VERSION ""

NS_ :

BS_:

BU_: Tank_Sensor1
VAL_TABLE_ FMS_PushButtonStates 1 "On" 0 "Off" ;
VAL_TABLE_ FMS_SSM 3 "Failure Warning " 2 "Functional Test" 1 "NCD" 0 "Normal Operation " ;
VAL_TABLE_ FMS_SDI 2 "Computer 2" 1 "Computer 1" ;
VAL_TABLE_ FMS_Pump_States 1 "Off" 0 "Energized" ;
VAL_TABLE_ vt_BNRaccuracy 1 "Degraded Accuracy" 0 "Nominal Accuracy" ;
VAL_TABLE_ vt_BCDstatus_above_below 3 "Below" 2 "FT (functional test)" 1 "NCD (no computed data)" 0 "Above" ;
VAL_TABLE_ vt_BCDstatus_to_from 3 "From" 2 "FT (functional test)" 1 "NCD (no computed data)" 0 "To" ;
VAL_TABLE_ vt_BCDstatus_right_left 3 "Left" 2 "FT (functional test)" 1 "NCD (no computed data)" 0 "Right" ;
VAL_TABLE_ vt_BCDstatus_east_west 3 "West" 2 "FT (functional test)" 1 "NCD (no computed data)" 0 "East" ;
VAL_TABLE_ vt_BCDstatus_north_south 3 "South" 2 "FT (functional test)" 1 "NCD (no computed data)" 0 "North" ;
VAL_TABLE_ vt_BCDstatus_plus_minus 3 "Minus" 2 "FT (functional test)" 1 "NCD (no computed data)" 0 "Plus" ;
VAL_TABLE_ vt_DSCstatus 3 "FW (failure warning)" 2 "FT (functional test)" 1 "NCD (no computed data)" 0 "NO (normal operation)" ;
VAL_TABLE_ vt_BNRsign_above_below 1 "Below" 0 "Above" ;
VAL_TABLE_ vt_BNRsign_to_from 1 "From" 0 "To" ;
VAL_TABLE_ vt_BNRsign_right_left 1 "Left" 0 "Right" ;
VAL_TABLE_ vt_BNRsign_east_west 1 "West" 0 "East" ;
VAL_TABLE_ vt_BNRsign_north_south 1 "South" 0 "North" ;
VAL_TABLE_ vt_BNRsign_plus_minus 1 "Minus" 0 "Plus" ;
VAL_TABLE_ vt_BNRstatus 3 "NO (normal operation)" 2 "FT (functional test)" 1 "NCD (no computed data)" 0 "FW (failure warning)" ;

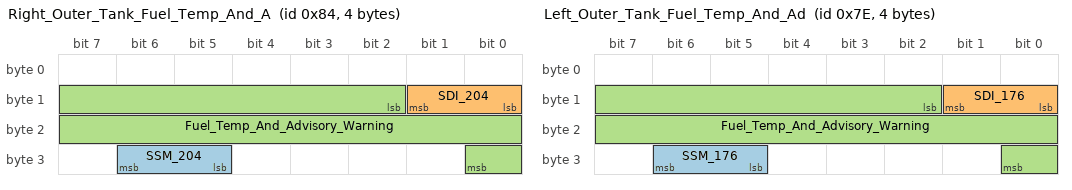
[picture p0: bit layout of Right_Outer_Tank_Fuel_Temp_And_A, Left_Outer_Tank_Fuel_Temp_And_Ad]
BO_ 132 Right_Outer_Tank_Fuel_Temp_And_A: 4 Tank_Sensor1
 SG_ SSM_204 : 29|2@1+ (1,0) [0|3] "" Vector__XXX
 SG_ SDI_204 : 8|2@1+ (1,0) [0|3] "" Vector__XXX
 SG_ Fuel_Temp_And_Advisory_Warning : 10|15@1- (0.25,0) [-512|512] "" Vector__XXX

BO_ 126 Left_Outer_Tank_Fuel_Temp_And_Ad: 4 Tank_Sensor1
 SG_ SSM_176 : 29|2@1+ (1,0) [0|3] "" Vector__XXX
 SG_ SDI_176 : 8|2@1+ (1,0) [0|3] "" Vector__XXX
 SG_ Fuel_Temp_And_Advisory_Warning : 10|15@1- (0.25,0) [-512|512] "" Vector__XXX

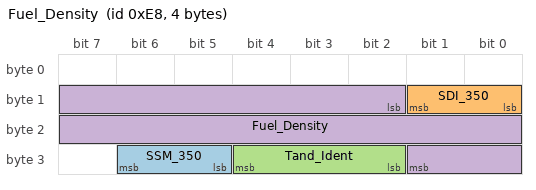
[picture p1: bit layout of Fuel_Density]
BO_ 232 Fuel_Density: 4 Tank_Sensor1
 SG_ SSM_350 : 29|2@1+ (1,0) [0|3] "" Vector__XXX
 SG_ SDI_350 : 8|2@1+ (1,0) [0|3] "" Vector__XXX
 SG_ Tand_Ident : 26|3@1+ (1,0) [0|7] "" Vector__XXX
 SG_ Fuel_Density : 10|16@1- (0.0001,0) [0|1] "kg/l" Vector__XXX

CM_ SG_ 132 SDI_204 "Source/Destination Identifier";
CM_ SG_ 126 SDI_176 "Source/Destination Identifier";
CM_ SG_ 232 SDI_350 "Source/Destination Identifier";
BA_DEF_  "ProtocolType" STRING ;
BA_DEF_ BO_  "A429SpecSource" ENUM  "ARINC","GAMA","Private";
BA_DEF_ BO_  "A429Protocol" ENUM  "BC","AIM","A619","WB1","WB2","WB3";
BA_DEF_ SG_  "A429SignalType" ENUM  "none","BCD","BNR","DISCRETE","ISO-5","SSM","SDI";
BA_DEF_  "A429Parity" ENUM  "unknown","odd","even";
BA_DEF_ BO_  "A429EquipmentId" HEX 0 4095;
BA_DEF_ BO_  "A429CycleMax" INT 0 0;
BA_DEF_ BO_  "A429Cycle" INT 0 0;
BA_DEF_ BO_  "A429CycleMin" INT 0 0;
BA_DEF_ BU_  "A429Equipment" STRING ;
BA_DEF_  "Baudrate" INT 10500 110000;
BA_DEF_  "ToolName" STRING ;
BA_DEF_  "ToolVersion" STRING ;
BA_DEF_  "Manufacturer" STRING ;
BA_DEF_  "VersionDay" INT 0 31;
BA_DEF_  "VersionMonth" INT 0 12;
BA_DEF_  "VersionWeek" INT 0 0;
BA_DEF_  "BusType" STRING ;
BA_DEF_ BO_  "SystemMessageLongSymbol" STRING ;
BA_DEF_DEF_  "ProtocolType" "Aerospace";
BA_DEF_DEF_  "A429SpecSource" "ARINC";
BA_DEF_DEF_  "A429Protocol" "BC";
BA_DEF_DEF_  "A429SignalType" "BNR";
BA_DEF_DEF_  "A429Parity" "odd";
BA_DEF_DEF_  "A429EquipmentId" 0;
BA_DEF_DEF_  "A429CycleMax" 0;
BA_DEF_DEF_  "A429Cycle" 0;
BA_DEF_DEF_  "A429CycleMin" 0;
BA_DEF_DEF_  "A429Equipment" "<unknown>";
BA_DEF_DEF_  "Baudrate" 100000;
BA_DEF_DEF_  "ToolName" "manually";
BA_DEF_DEF_  "ToolVersion" "x.y.z.n";
BA_DEF_DEF_  "Manufacturer" "<unknown>";
BA_DEF_DEF_  "VersionDay" 1;
BA_DEF_DEF_  "VersionMonth" 1;
BA_DEF_DEF_  "VersionWeek" 1;
BA_DEF_DEF_  "BusType" "ARINC429";
BA_DEF_DEF_  "SystemMessageLongSymbol" "";
BA_ "A429Equipment" BU_ Tank_Sensor1 "114";
BA_ "A429CycleMax" BO_ 132 400000;
BA_ "A429Cycle" BO_ 132 250000;
BA_ "A429CycleMin" BO_ 132 100000;
BA_ "SystemMessageLongSymbol" BO_ 132 "Right_Outer_Tank_Fuel_Temp_And_Advisory_Warning";
BA_ "A429CycleMax" BO_ 126 400000;
BA_ "A429Cycle" BO_ 126 250000;
BA_ "A429CycleMin" BO_ 126 100000;
BA_ "SystemMessageLongSymbol" BO_ 126 "Left_Outer_Tank_Fuel_Temp_And_Advisory_Warning";
BA_ "A429CycleMin" BO_ 232 100000;
BA_ "A429Cycle" BO_ 232 400000;
BA_ "A429CycleMax" BO_ 232 500000;
BA_ "A429EquipmentId" BO_ 232 276;
VAL_ 132 SSM_204 3 "Failure Warning " 2 "Functional Test" 1 "NCD" 0 "Normal Operation " ;
VAL_ 126 SSM_176 3 "Failure Warning " 2 "Functional Test" 1 "NCD" 0 "Normal Operation " ;
VAL_ 232 SSM_350 3 "Failure Warning " 2 "Functional Test" 1 "NCD" 0 "Normal Operation " ;
SIG_VALTYPE_ 232 Fuel_Density : 2;
